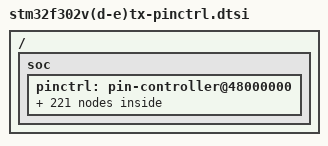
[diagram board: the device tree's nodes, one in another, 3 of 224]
/*
 * NOTE: Autogenerated file using genpinctrl.py
 *
 * SPDX-License-Identifier: Apache-2.0
 */

#include <dt-bindings/pinctrl/stm32-pinctrl.h>

/ {
	soc {
		pinctrl: pin-controller@48000000 {

			/* ADC_IN / ADC_INN / ADC_INP */

			adc1_in1_pa0: adc1_in1_pa0 {
				pinmux = <STM32_PINMUX('A', 0, ANALOG)>;
			};

			adc1_in2_pa1: adc1_in2_pa1 {
				pinmux = <STM32_PINMUX('A', 1, ANALOG)>;
			};

			adc1_in3_pa2: adc1_in3_pa2 {
				pinmux = <STM32_PINMUX('A', 2, ANALOG)>;
			};

			adc1_in4_pa3: adc1_in4_pa3 {
				pinmux = <STM32_PINMUX('A', 3, ANALOG)>;
			};

			adc1_in14_pb11: adc1_in14_pb11 {
				pinmux = <STM32_PINMUX('B', 11, ANALOG)>;
			};

			adc1_in6_pc0: adc1_in6_pc0 {
				pinmux = <STM32_PINMUX('C', 0, ANALOG)>;
			};

			adc1_in7_pc1: adc1_in7_pc1 {
				pinmux = <STM32_PINMUX('C', 1, ANALOG)>;
			};

			adc1_in8_pc2: adc1_in8_pc2 {
				pinmux = <STM32_PINMUX('C', 2, ANALOG)>;
			};

			adc1_in9_pc3: adc1_in9_pc3 {
				pinmux = <STM32_PINMUX('C', 3, ANALOG)>;
			};

			adc1_in10_pf2: adc1_in10_pf2 {
				pinmux = <STM32_PINMUX('F', 2, ANALOG)>;
			};

			adc2_in1_pa4: adc2_in1_pa4 {
				pinmux = <STM32_PINMUX('A', 4, ANALOG)>;
			};

			adc2_in2_pa5: adc2_in2_pa5 {
				pinmux = <STM32_PINMUX('A', 5, ANALOG)>;
			};

			adc2_in3_pa6: adc2_in3_pa6 {
				pinmux = <STM32_PINMUX('A', 6, ANALOG)>;
			};

			adc2_in4_pa7: adc2_in4_pa7 {
				pinmux = <STM32_PINMUX('A', 7, ANALOG)>;
			};

			adc2_in12_pb2: adc2_in12_pb2 {
				pinmux = <STM32_PINMUX('B', 2, ANALOG)>;
			};

			adc2_in14_pb11: adc2_in14_pb11 {
				pinmux = <STM32_PINMUX('B', 11, ANALOG)>;
			};

			adc2_in6_pc0: adc2_in6_pc0 {
				pinmux = <STM32_PINMUX('C', 0, ANALOG)>;
			};

			adc2_in7_pc1: adc2_in7_pc1 {
				pinmux = <STM32_PINMUX('C', 1, ANALOG)>;
			};

			adc2_in8_pc2: adc2_in8_pc2 {
				pinmux = <STM32_PINMUX('C', 2, ANALOG)>;
			};

			adc2_in9_pc3: adc2_in9_pc3 {
				pinmux = <STM32_PINMUX('C', 3, ANALOG)>;
			};

			adc2_in5_pc4: adc2_in5_pc4 {
				pinmux = <STM32_PINMUX('C', 4, ANALOG)>;
			};

			adc2_in11_pc5: adc2_in11_pc5 {
				pinmux = <STM32_PINMUX('C', 5, ANALOG)>;
			};

			adc2_in10_pf2: adc2_in10_pf2 {
				pinmux = <STM32_PINMUX('F', 2, ANALOG)>;
			};

			/* CAN_RX */

			can_rx_pa11: can_rx_pa11 {
				pinmux = <STM32_PINMUX('A', 11, AF9)>;
				bias-pull-up;
			};

			can_rx_pb8: can_rx_pb8 {
				pinmux = <STM32_PINMUX('B', 8, AF9)>;
				bias-pull-up;
			};

			can_rx_pd0: can_rx_pd0 {
				pinmux = <STM32_PINMUX('D', 0, AF7)>;
				bias-pull-up;
			};

			/* CAN_TX */

			can_tx_pa12: can_tx_pa12 {
				pinmux = <STM32_PINMUX('A', 12, AF9)>;
			};

			can_tx_pb9: can_tx_pb9 {
				pinmux = <STM32_PINMUX('B', 9, AF9)>;
			};

			can_tx_pd1: can_tx_pd1 {
				pinmux = <STM32_PINMUX('D', 1, AF7)>;
			};

			/* DAC_OUT */

			dac1_out1_pa4: dac1_out1_pa4 {
				pinmux = <STM32_PINMUX('A', 4, ANALOG)>;
			};

			/* I2C_SCL */

			i2c1_scl_pa15: i2c1_scl_pa15 {
				pinmux = <STM32_PINMUX('A', 15, AF4)>;
				bias-pull-up;
				drive-open-drain;
			};

			i2c1_scl_pb6: i2c1_scl_pb6 {
				pinmux = <STM32_PINMUX('B', 6, AF4)>;
				bias-pull-up;
				drive-open-drain;
			};

			i2c1_scl_pb8: i2c1_scl_pb8 {
				pinmux = <STM32_PINMUX('B', 8, AF4)>;
				bias-pull-up;
				drive-open-drain;
			};

			i2c2_scl_pa9: i2c2_scl_pa9 {
				pinmux = <STM32_PINMUX('A', 9, AF4)>;
				bias-pull-up;
				drive-open-drain;
			};

			i2c2_scl_pf1: i2c2_scl_pf1 {
				pinmux = <STM32_PINMUX('F', 1, AF4)>;
				bias-pull-up;
				drive-open-drain;
			};

			i2c2_scl_pf6: i2c2_scl_pf6 {
				pinmux = <STM32_PINMUX('F', 6, AF4)>;
				bias-pull-up;
				drive-open-drain;
			};

			i2c3_scl_pa8: i2c3_scl_pa8 {
				pinmux = <STM32_PINMUX('A', 8, AF3)>;
				bias-pull-up;
				drive-open-drain;
			};

			/* I2C_SDA */

			i2c1_sda_pa14: i2c1_sda_pa14 {
				pinmux = <STM32_PINMUX('A', 14, AF4)>;
				bias-pull-up;
				drive-open-drain;
			};

			i2c1_sda_pb7: i2c1_sda_pb7 {
				pinmux = <STM32_PINMUX('B', 7, AF4)>;
				bias-pull-up;
				drive-open-drain;
			};

			i2c1_sda_pb9: i2c1_sda_pb9 {
				pinmux = <STM32_PINMUX('B', 9, AF4)>;
				bias-pull-up;
				drive-open-drain;
			};

			i2c2_sda_pa10: i2c2_sda_pa10 {
				pinmux = <STM32_PINMUX('A', 10, AF4)>;
				bias-pull-up;
				drive-open-drain;
			};

			i2c2_sda_pf0: i2c2_sda_pf0 {
				pinmux = <STM32_PINMUX('F', 0, AF4)>;
				bias-pull-up;
				drive-open-drain;
			};

			i2c3_sda_pb5: i2c3_sda_pb5 {
				pinmux = <STM32_PINMUX('B', 5, AF8)>;
				bias-pull-up;
				drive-open-drain;
			};

			i2c3_sda_pc9: i2c3_sda_pc9 {
				pinmux = <STM32_PINMUX('C', 9, AF3)>;
				bias-pull-up;
				drive-open-drain;
			};

			/* I2S_CK */

			i2s2_ck_pb13: i2s2_ck_pb13 {
				pinmux = <STM32_PINMUX('B', 13, AF5)>;
			};

			i2s2_ck_pf1: i2s2_ck_pf1 {
				pinmux = <STM32_PINMUX('F', 1, AF5)>;
			};

			i2s3_ck_pb3: i2s3_ck_pb3 {
				pinmux = <STM32_PINMUX('B', 3, AF6)>;
			};

			i2s3_ck_pc10: i2s3_ck_pc10 {
				pinmux = <STM32_PINMUX('C', 10, AF6)>;
			};

			/* I2S_SD */

			i2s2_sd_pa11: i2s2_sd_pa11 {
				pinmux = <STM32_PINMUX('A', 11, AF5)>;
			};

			i2s2_sd_pb15: i2s2_sd_pb15 {
				pinmux = <STM32_PINMUX('B', 15, AF5)>;
			};

			i2s3_sd_pb5: i2s3_sd_pb5 {
				pinmux = <STM32_PINMUX('B', 5, AF6)>;
			};

			i2s3_sd_pc12: i2s3_sd_pc12 {
				pinmux = <STM32_PINMUX('C', 12, AF6)>;
			};

			/* I2S_WS */

			i2s2_ws_pb12: i2s2_ws_pb12 {
				pinmux = <STM32_PINMUX('B', 12, AF5)>;
			};

			i2s2_ws_pf0: i2s2_ws_pf0 {
				pinmux = <STM32_PINMUX('F', 0, AF5)>;
			};

			i2s3_ws_pa4: i2s3_ws_pa4 {
				pinmux = <STM32_PINMUX('A', 4, AF6)>;
			};

			i2s3_ws_pa15: i2s3_ws_pa15 {
				pinmux = <STM32_PINMUX('A', 15, AF6)>;
			};

			/* SPI_MISO */

			spi1_miso_pa6: spi1_miso_pa6 {
				pinmux = <STM32_PINMUX('A', 6, AF5)>;
				bias-pull-down;
			};

			spi1_miso_pb4: spi1_miso_pb4 {
				pinmux = <STM32_PINMUX('B', 4, AF5)>;
				bias-pull-down;
			};

			spi2_miso_pa10: spi2_miso_pa10 {
				pinmux = <STM32_PINMUX('A', 10, AF5)>;
				bias-pull-down;
			};

			spi2_miso_pb14: spi2_miso_pb14 {
				pinmux = <STM32_PINMUX('B', 14, AF5)>;
				bias-pull-down;
			};

			spi3_miso_pb4: spi3_miso_pb4 {
				pinmux = <STM32_PINMUX('B', 4, AF6)>;
				bias-pull-down;
			};

			spi3_miso_pc11: spi3_miso_pc11 {
				pinmux = <STM32_PINMUX('C', 11, AF6)>;
				bias-pull-down;
			};

			spi4_miso_pe5: spi4_miso_pe5 {
				pinmux = <STM32_PINMUX('E', 5, AF5)>;
				bias-pull-down;
			};

			spi4_miso_pe13: spi4_miso_pe13 {
				pinmux = <STM32_PINMUX('E', 13, AF5)>;
				bias-pull-down;
			};

			/* SPI_MOSI */

			spi1_mosi_pa7: spi1_mosi_pa7 {
				pinmux = <STM32_PINMUX('A', 7, AF5)>;
				bias-pull-down;
			};

			spi1_mosi_pb5: spi1_mosi_pb5 {
				pinmux = <STM32_PINMUX('B', 5, AF5)>;
				bias-pull-down;
			};

			spi2_mosi_pa11: spi2_mosi_pa11 {
				pinmux = <STM32_PINMUX('A', 11, AF5)>;
				bias-pull-down;
			};

			spi2_mosi_pb15: spi2_mosi_pb15 {
				pinmux = <STM32_PINMUX('B', 15, AF5)>;
				bias-pull-down;
			};

			spi3_mosi_pb5: spi3_mosi_pb5 {
				pinmux = <STM32_PINMUX('B', 5, AF6)>;
				bias-pull-down;
			};

			spi3_mosi_pc12: spi3_mosi_pc12 {
				pinmux = <STM32_PINMUX('C', 12, AF6)>;
				bias-pull-down;
			};

			spi4_mosi_pe6: spi4_mosi_pe6 {
				pinmux = <STM32_PINMUX('E', 6, AF5)>;
				bias-pull-down;
			};

			spi4_mosi_pe14: spi4_mosi_pe14 {
				pinmux = <STM32_PINMUX('E', 14, AF5)>;
				bias-pull-down;
			};

			/* SPI_NSS */

			spi1_nss_pa4: spi1_nss_pa4 {
				pinmux = <STM32_PINMUX('A', 4, AF5)>;
				bias-pull-up;
			};

			spi1_nss_pa15: spi1_nss_pa15 {
				pinmux = <STM32_PINMUX('A', 15, AF5)>;
				bias-pull-up;
			};

			spi2_nss_pb12: spi2_nss_pb12 {
				pinmux = <STM32_PINMUX('B', 12, AF5)>;
				bias-pull-up;
			};

			spi2_nss_pd15: spi2_nss_pd15 {
				pinmux = <STM32_PINMUX('D', 15, AF6)>;
				bias-pull-up;
			};

			spi2_nss_pf0: spi2_nss_pf0 {
				pinmux = <STM32_PINMUX('F', 0, AF5)>;
				bias-pull-up;
			};

			spi3_nss_pa4: spi3_nss_pa4 {
				pinmux = <STM32_PINMUX('A', 4, AF6)>;
				bias-pull-up;
			};

			spi3_nss_pa15: spi3_nss_pa15 {
				pinmux = <STM32_PINMUX('A', 15, AF6)>;
				bias-pull-up;
			};

			spi4_nss_pe3: spi4_nss_pe3 {
				pinmux = <STM32_PINMUX('E', 3, AF5)>;
				bias-pull-up;
			};

			spi4_nss_pe4: spi4_nss_pe4 {
				pinmux = <STM32_PINMUX('E', 4, AF5)>;
				bias-pull-up;
			};

			spi4_nss_pe11: spi4_nss_pe11 {
				pinmux = <STM32_PINMUX('E', 11, AF5)>;
				bias-pull-up;
			};

			/* SPI_SCK */

			spi1_sck_pa5: spi1_sck_pa5 {
				pinmux = <STM32_PINMUX('A', 5, AF5)>;
				slew-rate = "very-high-speed";
			};

			spi1_sck_pb3: spi1_sck_pb3 {
				pinmux = <STM32_PINMUX('B', 3, AF5)>;
				slew-rate = "very-high-speed";
			};

			spi2_sck_pb13: spi2_sck_pb13 {
				pinmux = <STM32_PINMUX('B', 13, AF5)>;
				slew-rate = "very-high-speed";
			};

			spi2_sck_pf1: spi2_sck_pf1 {
				pinmux = <STM32_PINMUX('F', 1, AF5)>;
				slew-rate = "very-high-speed";
			};

			spi2_sck_pf9: spi2_sck_pf9 {
				pinmux = <STM32_PINMUX('F', 9, AF5)>;
				slew-rate = "very-high-speed";
			};

			spi2_sck_pf10: spi2_sck_pf10 {
				pinmux = <STM32_PINMUX('F', 10, AF5)>;
				slew-rate = "very-high-speed";
			};

			spi3_sck_pb3: spi3_sck_pb3 {
				pinmux = <STM32_PINMUX('B', 3, AF6)>;
				slew-rate = "very-high-speed";
			};

			spi3_sck_pc10: spi3_sck_pc10 {
				pinmux = <STM32_PINMUX('C', 10, AF6)>;
				slew-rate = "very-high-speed";
			};

			spi4_sck_pe2: spi4_sck_pe2 {
				pinmux = <STM32_PINMUX('E', 2, AF5)>;
				slew-rate = "very-high-speed";
			};

			spi4_sck_pe12: spi4_sck_pe12 {
				pinmux = <STM32_PINMUX('E', 12, AF5)>;
				slew-rate = "very-high-speed";
			};

			/* TIM_CH_PWM / TIM_CHN_PWM */

			tim1_ch1n_pwm_pa7: tim1_ch1n_pwm_pa7 {
				pinmux = <STM32_PINMUX('A', 7, AF6)>;
			};

			tim1_ch1_pwm_pa8: tim1_ch1_pwm_pa8 {
				pinmux = <STM32_PINMUX('A', 8, AF6)>;
			};

			tim1_ch2_pwm_pa9: tim1_ch2_pwm_pa9 {
				pinmux = <STM32_PINMUX('A', 9, AF6)>;
			};

			tim1_ch3_pwm_pa10: tim1_ch3_pwm_pa10 {
				pinmux = <STM32_PINMUX('A', 10, AF6)>;
			};

			tim1_ch1n_pwm_pa11: tim1_ch1n_pwm_pa11 {
				pinmux = <STM32_PINMUX('A', 11, AF6)>;
			};

			tim1_ch4_pwm_pa11: tim1_ch4_pwm_pa11 {
				pinmux = <STM32_PINMUX('A', 11, AF11)>;
			};

			tim1_ch2n_pwm_pa12: tim1_ch2n_pwm_pa12 {
				pinmux = <STM32_PINMUX('A', 12, AF6)>;
			};

			tim1_ch2n_pwm_pb0: tim1_ch2n_pwm_pb0 {
				pinmux = <STM32_PINMUX('B', 0, AF6)>;
			};

			tim1_ch3n_pwm_pb1: tim1_ch3n_pwm_pb1 {
				pinmux = <STM32_PINMUX('B', 1, AF6)>;
			};

			tim1_ch1n_pwm_pb13: tim1_ch1n_pwm_pb13 {
				pinmux = <STM32_PINMUX('B', 13, AF6)>;
			};

			tim1_ch2n_pwm_pb14: tim1_ch2n_pwm_pb14 {
				pinmux = <STM32_PINMUX('B', 14, AF6)>;
			};

			tim1_ch3n_pwm_pb15: tim1_ch3n_pwm_pb15 {
				pinmux = <STM32_PINMUX('B', 15, AF4)>;
			};

			tim1_ch1_pwm_pc0: tim1_ch1_pwm_pc0 {
				pinmux = <STM32_PINMUX('C', 0, AF2)>;
			};

			tim1_ch2_pwm_pc1: tim1_ch2_pwm_pc1 {
				pinmux = <STM32_PINMUX('C', 1, AF2)>;
			};

			tim1_ch3_pwm_pc2: tim1_ch3_pwm_pc2 {
				pinmux = <STM32_PINMUX('C', 2, AF2)>;
			};

			tim1_ch4_pwm_pc3: tim1_ch4_pwm_pc3 {
				pinmux = <STM32_PINMUX('C', 3, AF2)>;
			};

			tim1_ch1n_pwm_pc13: tim1_ch1n_pwm_pc13 {
				pinmux = <STM32_PINMUX('C', 13, AF4)>;
			};

			tim1_ch1n_pwm_pe8: tim1_ch1n_pwm_pe8 {
				pinmux = <STM32_PINMUX('E', 8, AF2)>;
			};

			tim1_ch1_pwm_pe9: tim1_ch1_pwm_pe9 {
				pinmux = <STM32_PINMUX('E', 9, AF2)>;
			};

			tim1_ch2n_pwm_pe10: tim1_ch2n_pwm_pe10 {
				pinmux = <STM32_PINMUX('E', 10, AF2)>;
			};

			tim1_ch2_pwm_pe11: tim1_ch2_pwm_pe11 {
				pinmux = <STM32_PINMUX('E', 11, AF2)>;
			};

			tim1_ch3n_pwm_pe12: tim1_ch3n_pwm_pe12 {
				pinmux = <STM32_PINMUX('E', 12, AF2)>;
			};

			tim1_ch3_pwm_pe13: tim1_ch3_pwm_pe13 {
				pinmux = <STM32_PINMUX('E', 13, AF2)>;
			};

			tim1_ch4_pwm_pe14: tim1_ch4_pwm_pe14 {
				pinmux = <STM32_PINMUX('E', 14, AF2)>;
			};

			tim1_ch3n_pwm_pf0: tim1_ch3n_pwm_pf0 {
				pinmux = <STM32_PINMUX('F', 0, AF6)>;
			};

			tim2_ch1_pwm_pa0: tim2_ch1_pwm_pa0 {
				pinmux = <STM32_PINMUX('A', 0, AF1)>;
			};

			tim2_ch2_pwm_pa1: tim2_ch2_pwm_pa1 {
				pinmux = <STM32_PINMUX('A', 1, AF1)>;
			};

			tim2_ch3_pwm_pa2: tim2_ch3_pwm_pa2 {
				pinmux = <STM32_PINMUX('A', 2, AF1)>;
			};

			tim2_ch4_pwm_pa3: tim2_ch4_pwm_pa3 {
				pinmux = <STM32_PINMUX('A', 3, AF1)>;
			};

			tim2_ch1_pwm_pa5: tim2_ch1_pwm_pa5 {
				pinmux = <STM32_PINMUX('A', 5, AF1)>;
			};

			tim2_ch3_pwm_pa9: tim2_ch3_pwm_pa9 {
				pinmux = <STM32_PINMUX('A', 9, AF10)>;
			};

			tim2_ch4_pwm_pa10: tim2_ch4_pwm_pa10 {
				pinmux = <STM32_PINMUX('A', 10, AF10)>;
			};

			tim2_ch1_pwm_pa15: tim2_ch1_pwm_pa15 {
				pinmux = <STM32_PINMUX('A', 15, AF1)>;
			};

			tim2_ch2_pwm_pb3: tim2_ch2_pwm_pb3 {
				pinmux = <STM32_PINMUX('B', 3, AF1)>;
			};

			tim2_ch3_pwm_pb10: tim2_ch3_pwm_pb10 {
				pinmux = <STM32_PINMUX('B', 10, AF1)>;
			};

			tim2_ch4_pwm_pb11: tim2_ch4_pwm_pb11 {
				pinmux = <STM32_PINMUX('B', 11, AF1)>;
			};

			tim2_ch1_pwm_pd3: tim2_ch1_pwm_pd3 {
				pinmux = <STM32_PINMUX('D', 3, AF2)>;
			};

			tim2_ch2_pwm_pd4: tim2_ch2_pwm_pd4 {
				pinmux = <STM32_PINMUX('D', 4, AF2)>;
			};

			tim2_ch4_pwm_pd6: tim2_ch4_pwm_pd6 {
				pinmux = <STM32_PINMUX('D', 6, AF2)>;
			};

			tim2_ch3_pwm_pd7: tim2_ch3_pwm_pd7 {
				pinmux = <STM32_PINMUX('D', 7, AF2)>;
			};

			tim3_ch2_pwm_pa4: tim3_ch2_pwm_pa4 {
				pinmux = <STM32_PINMUX('A', 4, AF2)>;
			};

			tim3_ch1_pwm_pa6: tim3_ch1_pwm_pa6 {
				pinmux = <STM32_PINMUX('A', 6, AF2)>;
			};

			tim3_ch2_pwm_pa7: tim3_ch2_pwm_pa7 {
				pinmux = <STM32_PINMUX('A', 7, AF2)>;
			};

			tim3_ch3_pwm_pb0: tim3_ch3_pwm_pb0 {
				pinmux = <STM32_PINMUX('B', 0, AF2)>;
			};

			tim3_ch4_pwm_pb1: tim3_ch4_pwm_pb1 {
				pinmux = <STM32_PINMUX('B', 1, AF2)>;
			};

			tim3_ch1_pwm_pb4: tim3_ch1_pwm_pb4 {
				pinmux = <STM32_PINMUX('B', 4, AF2)>;
			};

			tim3_ch2_pwm_pb5: tim3_ch2_pwm_pb5 {
				pinmux = <STM32_PINMUX('B', 5, AF2)>;
			};

			tim3_ch4_pwm_pb7: tim3_ch4_pwm_pb7 {
				pinmux = <STM32_PINMUX('B', 7, AF10)>;
			};

			tim3_ch1_pwm_pc6: tim3_ch1_pwm_pc6 {
				pinmux = <STM32_PINMUX('C', 6, AF2)>;
			};

			tim3_ch2_pwm_pc7: tim3_ch2_pwm_pc7 {
				pinmux = <STM32_PINMUX('C', 7, AF2)>;
			};

			tim3_ch3_pwm_pc8: tim3_ch3_pwm_pc8 {
				pinmux = <STM32_PINMUX('C', 8, AF2)>;
			};

			tim3_ch4_pwm_pc9: tim3_ch4_pwm_pc9 {
				pinmux = <STM32_PINMUX('C', 9, AF2)>;
			};

			tim3_ch1_pwm_pe2: tim3_ch1_pwm_pe2 {
				pinmux = <STM32_PINMUX('E', 2, AF2)>;
			};

			tim3_ch2_pwm_pe3: tim3_ch2_pwm_pe3 {
				pinmux = <STM32_PINMUX('E', 3, AF2)>;
			};

			tim3_ch3_pwm_pe4: tim3_ch3_pwm_pe4 {
				pinmux = <STM32_PINMUX('E', 4, AF2)>;
			};

			tim3_ch4_pwm_pe5: tim3_ch4_pwm_pe5 {
				pinmux = <STM32_PINMUX('E', 5, AF2)>;
			};

			tim4_ch1_pwm_pa11: tim4_ch1_pwm_pa11 {
				pinmux = <STM32_PINMUX('A', 11, AF10)>;
			};

			tim4_ch2_pwm_pa12: tim4_ch2_pwm_pa12 {
				pinmux = <STM32_PINMUX('A', 12, AF10)>;
			};

			tim4_ch3_pwm_pa13: tim4_ch3_pwm_pa13 {
				pinmux = <STM32_PINMUX('A', 13, AF10)>;
			};

			tim4_ch1_pwm_pb6: tim4_ch1_pwm_pb6 {
				pinmux = <STM32_PINMUX('B', 6, AF2)>;
			};

			tim4_ch2_pwm_pb7: tim4_ch2_pwm_pb7 {
				pinmux = <STM32_PINMUX('B', 7, AF2)>;
			};

			tim4_ch3_pwm_pb8: tim4_ch3_pwm_pb8 {
				pinmux = <STM32_PINMUX('B', 8, AF2)>;
			};

			tim4_ch4_pwm_pb9: tim4_ch4_pwm_pb9 {
				pinmux = <STM32_PINMUX('B', 9, AF2)>;
			};

			tim4_ch1_pwm_pd12: tim4_ch1_pwm_pd12 {
				pinmux = <STM32_PINMUX('D', 12, AF2)>;
			};

			tim4_ch2_pwm_pd13: tim4_ch2_pwm_pd13 {
				pinmux = <STM32_PINMUX('D', 13, AF2)>;
			};

			tim4_ch3_pwm_pd14: tim4_ch3_pwm_pd14 {
				pinmux = <STM32_PINMUX('D', 14, AF2)>;
			};

			tim4_ch4_pwm_pd15: tim4_ch4_pwm_pd15 {
				pinmux = <STM32_PINMUX('D', 15, AF2)>;
			};

			tim4_ch4_pwm_pf6: tim4_ch4_pwm_pf6 {
				pinmux = <STM32_PINMUX('F', 6, AF2)>;
			};

			tim15_ch1n_pwm_pa1: tim15_ch1n_pwm_pa1 {
				pinmux = <STM32_PINMUX('A', 1, AF9)>;
			};

			tim15_ch1_pwm_pa2: tim15_ch1_pwm_pa2 {
				pinmux = <STM32_PINMUX('A', 2, AF9)>;
			};

			tim15_ch2_pwm_pa3: tim15_ch2_pwm_pa3 {
				pinmux = <STM32_PINMUX('A', 3, AF9)>;
			};

			tim15_ch1_pwm_pb14: tim15_ch1_pwm_pb14 {
				pinmux = <STM32_PINMUX('B', 14, AF1)>;
			};

			tim15_ch1n_pwm_pb15: tim15_ch1n_pwm_pb15 {
				pinmux = <STM32_PINMUX('B', 15, AF2)>;
			};

			tim15_ch2_pwm_pb15: tim15_ch2_pwm_pb15 {
				pinmux = <STM32_PINMUX('B', 15, AF1)>;
			};

			tim15_ch1_pwm_pf9: tim15_ch1_pwm_pf9 {
				pinmux = <STM32_PINMUX('F', 9, AF3)>;
			};

			tim15_ch2_pwm_pf10: tim15_ch2_pwm_pf10 {
				pinmux = <STM32_PINMUX('F', 10, AF3)>;
			};

			tim16_ch1_pwm_pa6: tim16_ch1_pwm_pa6 {
				pinmux = <STM32_PINMUX('A', 6, AF1)>;
			};

			tim16_ch1_pwm_pa12: tim16_ch1_pwm_pa12 {
				pinmux = <STM32_PINMUX('A', 12, AF1)>;
			};

			tim16_ch1n_pwm_pa13: tim16_ch1n_pwm_pa13 {
				pinmux = <STM32_PINMUX('A', 13, AF1)>;
			};

			tim16_ch1_pwm_pb4: tim16_ch1_pwm_pb4 {
				pinmux = <STM32_PINMUX('B', 4, AF1)>;
			};

			tim16_ch1n_pwm_pb6: tim16_ch1n_pwm_pb6 {
				pinmux = <STM32_PINMUX('B', 6, AF1)>;
			};

			tim16_ch1_pwm_pb8: tim16_ch1_pwm_pb8 {
				pinmux = <STM32_PINMUX('B', 8, AF1)>;
			};

			tim16_ch1_pwm_pe0: tim16_ch1_pwm_pe0 {
				pinmux = <STM32_PINMUX('E', 0, AF4)>;
			};

			tim17_ch1_pwm_pa7: tim17_ch1_pwm_pa7 {
				pinmux = <STM32_PINMUX('A', 7, AF1)>;
			};

			tim17_ch1_pwm_pb5: tim17_ch1_pwm_pb5 {
				pinmux = <STM32_PINMUX('B', 5, AF10)>;
			};

			tim17_ch1n_pwm_pb7: tim17_ch1n_pwm_pb7 {
				pinmux = <STM32_PINMUX('B', 7, AF1)>;
			};

			tim17_ch1_pwm_pb9: tim17_ch1_pwm_pb9 {
				pinmux = <STM32_PINMUX('B', 9, AF1)>;
			};

			tim17_ch1_pwm_pe1: tim17_ch1_pwm_pe1 {
				pinmux = <STM32_PINMUX('E', 1, AF4)>;
			};

			/* UART_CTS / USART_CTS / LPUART_CTS */

			usart1_cts_pa11: usart1_cts_pa11 {
				pinmux = <STM32_PINMUX('A', 11, AF7)>;
				bias-pull-up;
				drive-open-drain;
			};

			usart2_cts_pa0: usart2_cts_pa0 {
				pinmux = <STM32_PINMUX('A', 0, AF7)>;
				bias-pull-up;
				drive-open-drain;
			};

			usart2_cts_pd3: usart2_cts_pd3 {
				pinmux = <STM32_PINMUX('D', 3, AF7)>;
				bias-pull-up;
				drive-open-drain;
			};

			usart3_cts_pa13: usart3_cts_pa13 {
				pinmux = <STM32_PINMUX('A', 13, AF7)>;
				bias-pull-up;
				drive-open-drain;
			};

			usart3_cts_pb13: usart3_cts_pb13 {
				pinmux = <STM32_PINMUX('B', 13, AF7)>;
				bias-pull-up;
				drive-open-drain;
			};

			usart3_cts_pd11: usart3_cts_pd11 {
				pinmux = <STM32_PINMUX('D', 11, AF7)>;
				bias-pull-up;
				drive-open-drain;
			};

			/* UART_RTS / USART_RTS / LPUART_RTS */

			usart1_rts_pa12: usart1_rts_pa12 {
				pinmux = <STM32_PINMUX('A', 12, AF7)>;
				bias-pull-up;
				drive-open-drain;
			};

			usart2_rts_pa1: usart2_rts_pa1 {
				pinmux = <STM32_PINMUX('A', 1, AF7)>;
				bias-pull-up;
				drive-open-drain;
			};

			usart2_rts_pd4: usart2_rts_pd4 {
				pinmux = <STM32_PINMUX('D', 4, AF7)>;
				bias-pull-up;
				drive-open-drain;
			};

			usart3_rts_pb14: usart3_rts_pb14 {
				pinmux = <STM32_PINMUX('B', 14, AF7)>;
				bias-pull-up;
				drive-open-drain;
			};

			usart3_rts_pd12: usart3_rts_pd12 {
				pinmux = <STM32_PINMUX('D', 12, AF7)>;
				bias-pull-up;
				drive-open-drain;
			};

			usart3_rts_pf6: usart3_rts_pf6 {
				pinmux = <STM32_PINMUX('F', 6, AF7)>;
				bias-pull-up;
				drive-open-drain;
			};

			/* UART_RX / USART_RX / LPUART_RX */

			usart1_rx_pa10: usart1_rx_pa10 {
				pinmux = <STM32_PINMUX('A', 10, AF7)>;
			};

			usart1_rx_pb7: usart1_rx_pb7 {
				pinmux = <STM32_PINMUX('B', 7, AF7)>;
			};

			usart1_rx_pc5: usart1_rx_pc5 {
				pinmux = <STM32_PINMUX('C', 5, AF7)>;
			};

			usart1_rx_pe1: usart1_rx_pe1 {
				pinmux = <STM32_PINMUX('E', 1, AF7)>;
			};

			usart2_rx_pa3: usart2_rx_pa3 {
				pinmux = <STM32_PINMUX('A', 3, AF7)>;
			};

			usart2_rx_pa15: usart2_rx_pa15 {
				pinmux = <STM32_PINMUX('A', 15, AF7)>;
			};

			usart2_rx_pb4: usart2_rx_pb4 {
				pinmux = <STM32_PINMUX('B', 4, AF7)>;
			};

			usart2_rx_pd6: usart2_rx_pd6 {
				pinmux = <STM32_PINMUX('D', 6, AF7)>;
			};

			usart3_rx_pb8: usart3_rx_pb8 {
				pinmux = <STM32_PINMUX('B', 8, AF7)>;
			};

			usart3_rx_pb11: usart3_rx_pb11 {
				pinmux = <STM32_PINMUX('B', 11, AF7)>;
			};

			usart3_rx_pc11: usart3_rx_pc11 {
				pinmux = <STM32_PINMUX('C', 11, AF7)>;
			};

			usart3_rx_pd9: usart3_rx_pd9 {
				pinmux = <STM32_PINMUX('D', 9, AF7)>;
			};

			usart3_rx_pe15: usart3_rx_pe15 {
				pinmux = <STM32_PINMUX('E', 15, AF7)>;
			};

			uart4_rx_pc11: uart4_rx_pc11 {
				pinmux = <STM32_PINMUX('C', 11, AF5)>;
			};

			uart5_rx_pd2: uart5_rx_pd2 {
				pinmux = <STM32_PINMUX('D', 2, AF5)>;
			};

			/* UART_TX / USART_TX / LPUART_TX */

			usart1_tx_pa9: usart1_tx_pa9 {
				pinmux = <STM32_PINMUX('A', 9, AF7)>;
				bias-pull-up;
			};

			usart1_tx_pb6: usart1_tx_pb6 {
				pinmux = <STM32_PINMUX('B', 6, AF7)>;
				bias-pull-up;
			};

			usart1_tx_pc4: usart1_tx_pc4 {
				pinmux = <STM32_PINMUX('C', 4, AF7)>;
				bias-pull-up;
			};

			usart1_tx_pe0: usart1_tx_pe0 {
				pinmux = <STM32_PINMUX('E', 0, AF7)>;
				bias-pull-up;
			};

			usart2_tx_pa2: usart2_tx_pa2 {
				pinmux = <STM32_PINMUX('A', 2, AF7)>;
				bias-pull-up;
			};

			usart2_tx_pa14: usart2_tx_pa14 {
				pinmux = <STM32_PINMUX('A', 14, AF7)>;
				bias-pull-up;
			};

			usart2_tx_pb3: usart2_tx_pb3 {
				pinmux = <STM32_PINMUX('B', 3, AF7)>;
				bias-pull-up;
			};

			usart2_tx_pd5: usart2_tx_pd5 {
				pinmux = <STM32_PINMUX('D', 5, AF7)>;
				bias-pull-up;
			};

			usart3_tx_pb9: usart3_tx_pb9 {
				pinmux = <STM32_PINMUX('B', 9, AF7)>;
				bias-pull-up;
			};

			usart3_tx_pb10: usart3_tx_pb10 {
				pinmux = <STM32_PINMUX('B', 10, AF7)>;
				bias-pull-up;
			};

			usart3_tx_pc10: usart3_tx_pc10 {
				pinmux = <STM32_PINMUX('C', 10, AF7)>;
				bias-pull-up;
			};

			usart3_tx_pd8: usart3_tx_pd8 {
				pinmux = <STM32_PINMUX('D', 8, AF7)>;
				bias-pull-up;
			};

			uart4_tx_pc10: uart4_tx_pc10 {
				pinmux = <STM32_PINMUX('C', 10, AF5)>;
				bias-pull-up;
			};

			uart5_tx_pc12: uart5_tx_pc12 {
				pinmux = <STM32_PINMUX('C', 12, AF5)>;
				bias-pull-up;
			};

		};
	};
};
